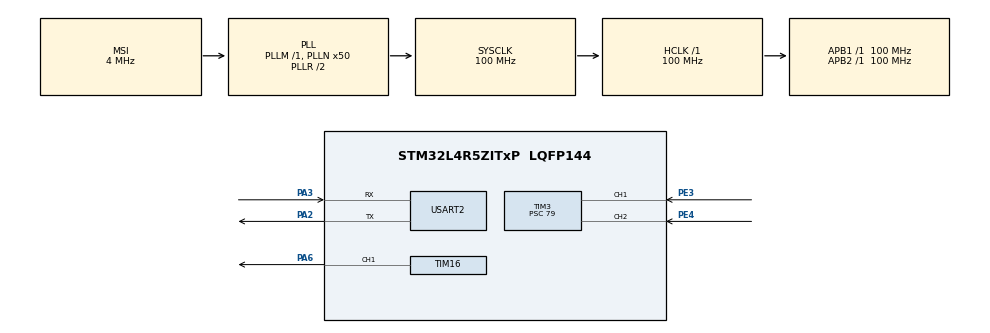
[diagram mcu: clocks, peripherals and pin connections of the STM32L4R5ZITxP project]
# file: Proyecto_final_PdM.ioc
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Mcu.Family=STM32L4
Mcu.Name=STM32L4R5ZITxP
Mcu.Package=LQFP144
NVIC.PriorityGroup=NVIC_PRIORITYGROUP_4
PA2.Mode=Asynchronous
PA2.Signal=USART2_TX
PA3.Mode=Asynchronous
PA3.Signal=USART2_RX
PA6.Signal=S_TIM16_CH1
PE3.Signal=S_TIM3_CH1
PE4.Signal=S_TIM3_CH2
ProjectManager.HeapSize=0x200
ProjectManager.StackSize=0x400
ProjectManager.TargetToolchain=STM32CubeIDE
RCC.ADCFreq_Value=48000000
RCC.AHBFreq_Value=100000000
RCC.APB1Freq_Value=100000000
RCC.APB1TimFreq_Value=100000000
RCC.APB2Freq_Value=100000000
RCC.APB2TimFreq_Value=100000000
RCC.CortexFreq_Value=100000000
RCC.HCLKFreq_Value=100000000
RCC.HSE_VALUE=8000000
RCC.HSI48_VALUE=48000000
RCC.HSI_VALUE=16000000
RCC.MSI_VALUE=4000000
RCC.PLLN=50
RCC.PLLSAI1N=24
RCC.SYSCLKFreq_VALUE=100000000
RCC.SYSCLKSource=RCC_SYSCLKSOURCE_PLLCLK
RCC.USBFreq_Value=48000000
RCC.VCOOutputFreq_Value=200000000
SH.S_TIM16_CH1.0=TIM16_CH1,PWM Generation1 CH1
SH.S_TIM3_CH1.0=TIM3_CH1,Input_Capture1_from_TI1
SH.S_TIM3_CH2.0=TIM3_CH2,TriggerSource_TI2FP2
SH.S_TIM3_CH2.1=TIM3_CH2,Input_Capture2_from_TI2
TIM16.Channel=TIM_CHANNEL_1
TIM16.Period=39999
TIM16.Prescaler=199
TIM3.Channel-Input_Capture1_from_TI1=TIM_CHANNEL_1
TIM3.Channel-Input_Capture2_from_TI2=TIM_CHANNEL_2
TIM3.ICPolarity_CH1=TIM_INPUTCHANNELPOLARITY_BOTHEDGE
TIM3.Prescaler=79
USART2.VirtualMode-Asynchronous=VM_ASYNC
VP_TIM16_VS_ClockSourceINT.Mode=Enable_Timer
VP_TIM3_VS_ControllerModeReset.Mode=Reset Mode
board=NUCLEO-L4R5ZI-P

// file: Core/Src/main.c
/* USER CODE BEGIN Header */
/**
  ******************************************************************************
  * @file           : main.c
  * @brief          : Main program body
  ******************************************************************************
  * @attention
  *
  * Copyright (c) 2022 STMicroelectronics.
  * All rights reserved.
  *
  * This software is licensed under terms that can be found in the LICENSE file
  * in the root directory of this software component.
  * If no LICENSE file comes with this software, it is provided AS-IS.
  *
  ******************************************************************************
  */
/* USER CODE END Header */
#include "main.h"
#include "tim.h"
#include "usart.h"
#include "gpio.h"

/* USER CODE BEGIN Includes */
#include "stdio.h"
/* USER CODE END Includes */

TIM_HandleTypeDef htim3;
TIM_HandleTypeDef htim16;

UART_HandleTypeDef huart2;

#ifdef __GNUC__
#define PUTCHAR_PROTOTYPE int __io_putchar(int ch)
#else
#define PUTCHAR PROTOTYPE int fputc(int ch, FILE *f)
#endif /* __GNUC__ */

PUTCHAR_PROTOTYPE
{
        HAL_UART_Transmit(&huart2, (uint8_t *)&ch, 1, 10);
return ch;
}

uint32_t echo1, echo2, delay;
float dist1, dist2;

void SystemClock_Config(void);
static void MX_GPIO_Init(void);
static void MX_USART2_UART_Init(void);
static void MX_TIM3_Init(void);
static void MX_TIM16_Init(void);

int main(void)
{

  /* MCU Configuration--------------------------------------------------------*/

  /* Reset of all peripherals, Initializes the Flash interface and the Systick. */
  HAL_Init();

  /* Configure the system clock */
  SystemClock_Config();

  /* Initialize all configured peripherals */
  MX_GPIO_Init();
  MX_USART2_UART_Init();
  MX_TIM3_Init();
  MX_TIM16_Init();
  /* USER CODE BEGIN 2 */
HAL_TIM_Base_Start(&htim16);
HAL_TIM_Base_Start(&htim16);
HAL_TIM_PWM_Start(&htim16, TIM_CHANNEL_1);
HAL_TIM_IC_Start(&htim3, TIM_CHANNEL_1);
HAL_TIM_IC_Start(&htim3, TIM_CHANNEL_1);
TIM16->CCR1=3;
  /* USER CODE END 2 */

  /* Infinite loop */
  /* USER CODE BEGIN WHILE */
  while (1)
  {
	  if(HAL_GetTick()- delay >= 100)
	  {
		  delay = HAL_GetTick();
		  echo1 = HAL_TIM_ReadCapturedValue(htim3, TIM_CHANNEL_1);
		  echo2 = HAL_TIM_ReadCapturedValue(htim3, TIM_CHANNEL_2);
		  dist1 = echo1/58.0f;
		  dist2 = echo1/58.0f;
		  printf("Echo1: %u dist1: %.2f Echo2: %u Echo2: %.2f\r\n", echo1, echo2, dist1, dist2); // @suppress("Float formatting support")
	  }
    /* USER CODE END WHILE */

  }
}

void SystemClock_Config(void)
{
  RCC_OscInitTypeDef RCC_OscInitStruct = {0};
  RCC_ClkInitTypeDef RCC_ClkInitStruct = {0};

  /** Configure the main internal regulator output voltage
  */
  if (HAL_PWREx_ControlVoltageScaling(PWR_REGULATOR_VOLTAGE_SCALE1_BOOST) != HAL_OK)
  {
    Error_Handler();
  }

  /** Initializes the RCC Oscillators according to the specified parameters
  * in the RCC_OscInitTypeDef structure.
  */
  RCC_OscInitStruct.OscillatorType = RCC_OSCILLATORTYPE_MSI;
  RCC_OscInitStruct.MSIState = RCC_MSI_ON;
  RCC_OscInitStruct.MSICalibrationValue = 0;
  RCC_OscInitStruct.MSIClockRange = RCC_MSIRANGE_6;
  RCC_OscInitStruct.PLL.PLLState = RCC_PLL_ON;
  RCC_OscInitStruct.PLL.PLLSource = RCC_PLLSOURCE_MSI;
  RCC_OscInitStruct.PLL.PLLM = 1;
  RCC_OscInitStruct.PLL.PLLN = 50;
  RCC_OscInitStruct.PLL.PLLP = RCC_PLLP_DIV2;
  RCC_OscInitStruct.PLL.PLLQ = RCC_PLLQ_DIV2;
  RCC_OscInitStruct.PLL.PLLR = RCC_PLLR_DIV2;
  if (HAL_RCC_OscConfig(&RCC_OscInitStruct) != HAL_OK)
  {
    Error_Handler();
  }

  /** Initializes the CPU, AHB and APB buses clocks
  */
  RCC_ClkInitStruct.ClockType = RCC_CLOCKTYPE_HCLK|RCC_CLOCKTYPE_SYSCLK
                              |RCC_CLOCKTYPE_PCLK1|RCC_CLOCKTYPE_PCLK2;
  RCC_ClkInitStruct.SYSCLKSource = RCC_SYSCLKSOURCE_PLLCLK;
  RCC_ClkInitStruct.AHBCLKDivider = RCC_SYSCLK_DIV1;
  RCC_ClkInitStruct.APB1CLKDivider = RCC_HCLK_DIV1;
  RCC_ClkInitStruct.APB2CLKDivider = RCC_HCLK_DIV1;

  if (HAL_RCC_ClockConfig(&RCC_ClkInitStruct, FLASH_LATENCY_4) != HAL_OK)
  {
    Error_Handler();
  }
}

static void MX_TIM3_Init(void)
{

  TIM_SlaveConfigTypeDef sSlaveConfig = {0};
  TIM_MasterConfigTypeDef sMasterConfig = {0};
  TIM_IC_InitTypeDef sConfigIC = {0};

  htim3.Instance = TIM3;
  htim3.Init.Prescaler = 79;
  htim3.Init.CounterMode = TIM_COUNTERMODE_UP;
  htim3.Init.Period = 65535;
  htim3.Init.ClockDivision = TIM_CLOCKDIVISION_DIV1;
  htim3.Init.AutoReloadPreload = TIM_AUTORELOAD_PRELOAD_DISABLE;
  if (HAL_TIM_Base_Init(&htim3) != HAL_OK)
  {
    Error_Handler();
  }
  if (HAL_TIM_IC_Init(&htim3) != HAL_OK)
  {
    Error_Handler();
  }
  sSlaveConfig.SlaveMode = TIM_SLAVEMODE_RESET;
  sSlaveConfig.InputTrigger = TIM_TS_TI2FP2;
  sSlaveConfig.TriggerPolarity = TIM_INPUTCHANNELPOLARITY_RISING;
  sSlaveConfig.TriggerFilter = 0;
  if (HAL_TIM_SlaveConfigSynchro(&htim3, &sSlaveConfig) != HAL_OK)
  {
    Error_Handler();
  }
  sMasterConfig.MasterOutputTrigger = TIM_TRGO_RESET;
  sMasterConfig.MasterSlaveMode = TIM_MASTERSLAVEMODE_DISABLE;
  if (HAL_TIMEx_MasterConfigSynchronization(&htim3, &sMasterConfig) != HAL_OK)
  {
    Error_Handler();
  }
  sConfigIC.ICPolarity = TIM_INPUTCHANNELPOLARITY_BOTHEDGE;
  sConfigIC.ICSelection = TIM_ICSELECTION_DIRECTTI;
  sConfigIC.ICPrescaler = TIM_ICPSC_DIV1;
  sConfigIC.ICFilter = 0;
  if (HAL_TIM_IC_ConfigChannel(&htim3, &sConfigIC, TIM_CHANNEL_1) != HAL_OK)
  {
    Error_Handler();
  }
  sConfigIC.ICPolarity = TIM_INPUTCHANNELPOLARITY_RISING;
  if (HAL_TIM_IC_ConfigChannel(&htim3, &sConfigIC, TIM_CHANNEL_2) != HAL_OK)
  {
    Error_Handler();
  }

}

static void MX_TIM16_Init(void)
{

  TIM_OC_InitTypeDef sConfigOC = {0};
  TIM_BreakDeadTimeConfigTypeDef sBreakDeadTimeConfig = {0};

  htim16.Instance = TIM16;
  htim16.Init.Prescaler = 199;
  htim16.Init.CounterMode = TIM_COUNTERMODE_UP;
  htim16.Init.Period = 39999;
  htim16.Init.ClockDivision = TIM_CLOCKDIVISION_DIV1;
  htim16.Init.RepetitionCounter = 0;
  htim16.Init.AutoReloadPreload = TIM_AUTORELOAD_PRELOAD_DISABLE;
  if (HAL_TIM_Base_Init(&htim16) != HAL_OK)
  {
    Error_Handler();
  }
  if (HAL_TIM_PWM_Init(&htim16) != HAL_OK)
  {
    Error_Handler();
  }
  sConfigOC.OCMode = TIM_OCMODE_PWM1;
  sConfigOC.Pulse = 0;
  sConfigOC.OCPolarity = TIM_OCPOLARITY_HIGH;
  sConfigOC.OCNPolarity = TIM_OCNPOLARITY_HIGH;
  sConfigOC.OCFastMode = TIM_OCFAST_DISABLE;
  sConfigOC.OCIdleState = TIM_OCIDLESTATE_RESET;
  sConfigOC.OCNIdleState = TIM_OCNIDLESTATE_RESET;
  if (HAL_TIM_PWM_ConfigChannel(&htim16, &sConfigOC, TIM_CHANNEL_1) != HAL_OK)
  {
    Error_Handler();
  }
  sBreakDeadTimeConfig.OffStateRunMode = TIM_OSSR_DISABLE;
  sBreakDeadTimeConfig.OffStateIDLEMode = TIM_OSSI_DISABLE;
  sBreakDeadTimeConfig.LockLevel = TIM_LOCKLEVEL_OFF;
  sBreakDeadTimeConfig.DeadTime = 0;
  sBreakDeadTimeConfig.BreakState = TIM_BREAK_DISABLE;
  sBreakDeadTimeConfig.BreakPolarity = TIM_BREAKPOLARITY_HIGH;
  sBreakDeadTimeConfig.AutomaticOutput = TIM_AUTOMATICOUTPUT_DISABLE;
  if (HAL_TIMEx_ConfigBreakDeadTime(&htim16, &sBreakDeadTimeConfig) != HAL_OK)
  {
    Error_Handler();
  }
  HAL_TIM_MspPostInit(&htim16);

}

static void MX_USART2_UART_Init(void)
{

  huart2.Instance = USART2;
  huart2.Init.BaudRate = 115200;
  huart2.Init.WordLength = UART_WORDLENGTH_8B;
  huart2.Init.StopBits = UART_STOPBITS_1;
  huart2.Init.Parity = UART_PARITY_NONE;
  huart2.Init.Mode = UART_MODE_TX_RX;
  huart2.Init.HwFlowCtl = UART_HWCONTROL_NONE;
  huart2.Init.OverSampling = UART_OVERSAMPLING_16;
  huart2.Init.OneBitSampling = UART_ONE_BIT_SAMPLE_DISABLE;
  huart2.Init.ClockPrescaler = UART_PRESCALER_DIV1;
  huart2.AdvancedInit.AdvFeatureInit = UART_ADVFEATURE_NO_INIT;
  if (HAL_UART_Init(&huart2) != HAL_OK)
  {
    Error_Handler();
  }
  if (HAL_UARTEx_SetTxFifoThreshold(&huart2, UART_TXFIFO_THRESHOLD_1_8) != HAL_OK)
  {
    Error_Handler();
  }
  if (HAL_UARTEx_SetRxFifoThreshold(&huart2, UART_RXFIFO_THRESHOLD_1_8) != HAL_OK)
  {
    Error_Handler();
  }
  if (HAL_UARTEx_DisableFifoMode(&huart2) != HAL_OK)
  {
    Error_Handler();
  }

}

static void MX_GPIO_Init(void)
{

  /* GPIO Ports Clock Enable */
  __HAL_RCC_GPIOE_CLK_ENABLE();
  __HAL_RCC_GPIOA_CLK_ENABLE();

}

void Error_Handler(void)
{
  __disable_irq();
  while (1)
  {
  }
}
